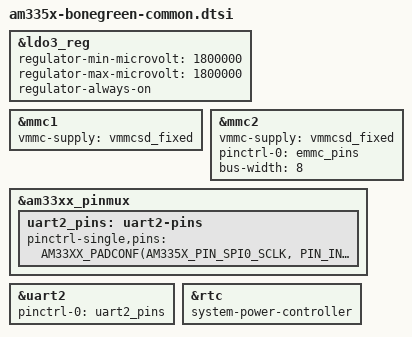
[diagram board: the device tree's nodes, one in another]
// SPDX-License-Identifier: GPL-2.0-only
/*
 * Copyright (C) 2012 Texas Instruments Incorporated - https://www.ti.com/
 */

&ldo3_reg {
	regulator-min-microvolt = <1800000>;
	regulator-max-microvolt = <1800000>;
	regulator-always-on;
};

&mmc1 {
	vmmc-supply = <&vmmcsd_fixed>;
};

&mmc2 {
	vmmc-supply = <&vmmcsd_fixed>;
	pinctrl-names = "default";
	pinctrl-0 = <&emmc_pins>;
	bus-width = <8>;
	status = "okay";
};

&am33xx_pinmux {
	uart2_pins: uart2-pins {
		pinctrl-single,pins = <
			AM33XX_PADCONF(AM335X_PIN_SPI0_SCLK, PIN_INPUT, MUX_MODE1)	/* spi0_sclk.uart2_rxd */
			AM33XX_PADCONF(AM335X_PIN_SPI0_D0, PIN_OUTPUT, MUX_MODE1)	/* spi0_d0.uart2_txd */
		>;
	};
};

&uart2 {
	pinctrl-names = "default";
	pinctrl-0 = <&uart2_pins>;
	status = "okay";
};

&rtc {
	system-power-controller;
};
